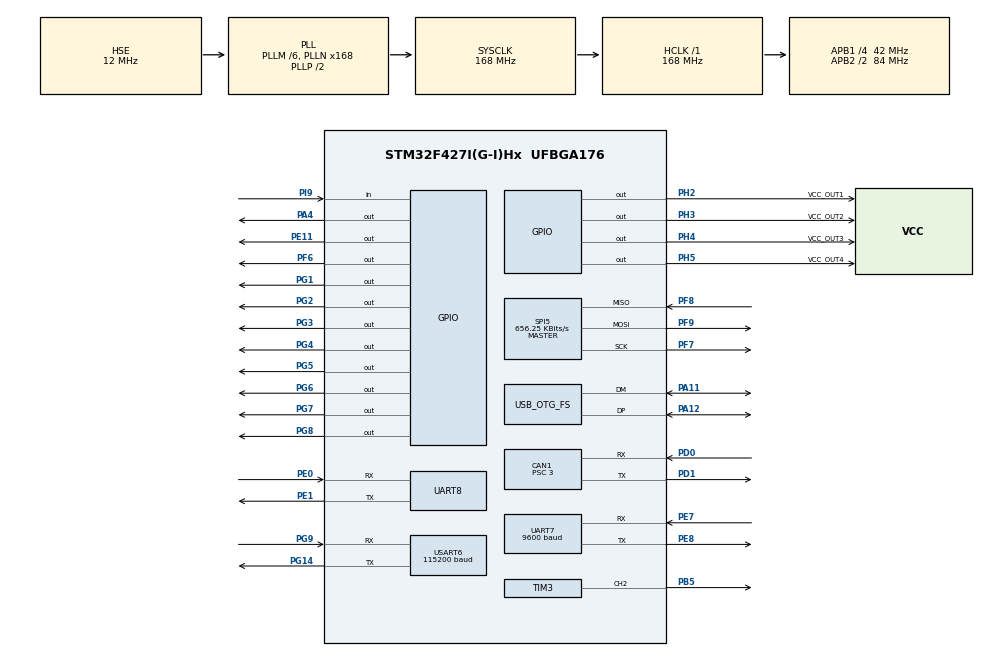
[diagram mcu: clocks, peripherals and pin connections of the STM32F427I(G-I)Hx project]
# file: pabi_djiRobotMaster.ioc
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CAN1.ABOM=ENABLE
CAN1.BS1=CAN_BS1_9TQ
CAN1.BS2=CAN_BS2_4TQ
CAN1.CalculateTimeQuantum=71.42857142857143
CAN1.Prescaler=3
FREERTOS.INCLUDE_xTaskGetHandle=1
FREERTOS.Tasks01=ledTask,0,128,LedTask,Default,NULL,Dynamic,NULL,NULL;defaultTask,0,128,StartDefaultTask,Default,NULL,Dynamic,NULL,NULL
FREERTOS.configENABLE_FPU=1
FREERTOS.configTOTAL_HEAP_SIZE=61440
Mcu.Family=STM32F4
Mcu.Name=STM32F427I(G-I)Hx
Mcu.Package=UFBGA176
NVIC.CAN1_RX0_IRQn=true\:5\:0\:false\:false\:true\:true\:true\:true
NVIC.OTG_FS_IRQn=true\:9\:0\:true\:false\:true\:false\:false\:true
NVIC.PriorityGroup=NVIC_PRIORITYGROUP_4
NVIC.TIM7_IRQn=true\:0\:0\:false\:false\:true\:false\:false\:true
NVIC.TimeBase=TIM7_IRQn
NVIC.TimeBaseIP=TIM7
NVIC.UART7_IRQn=true\:5\:0\:false\:false\:true\:true\:true\:true
NVIC.UART8_IRQn=true\:5\:0\:false\:false\:true\:true\:true\:true
NVIC.USART6_IRQn=true\:10\:0\:true\:false\:true\:false\:true\:true
PA11.Mode=Device_Only
PA11.Signal=USB_OTG_FS_DM
PA12.Mode=Device_Only
PA12.Signal=USB_OTG_FS_DP
PA13.Mode=Serial_Wire
PA13.Signal=SYS_JTMS-SWDIO
PA14.Mode=Serial_Wire
PA14.Signal=SYS_JTCK-SWCLK
PA4.GPIO_ModeDefaultOutputPP=GPIO_MODE_OUTPUT_PP
PA4.GPIO_PuPd=GPIO_PULLDOWN
PA4.Signal=GPIO_Output
PB5.GPIO_PuPd=GPIO_PULLUP
PB5.GPIO_Speed=GPIO_SPEED_FREQ_HIGH
PB5.Signal=S_TIM3_CH2
PD0.Mode=Master
PD0.Signal=CAN1_RX
PD1.Mode=Master
PD1.Signal=CAN1_TX
PE0.Mode=Asynchronous
PE0.Signal=UART8_RX
PE1.Mode=Asynchronous
PE1.Signal=UART8_TX
PE11.GPIO_ModeDefaultOutputPP=GPIO_MODE_OUTPUT_PP
PE11.GPIO_PuPd=GPIO_PULLDOWN
PE11.Signal=GPIO_Output
PE7.GPIO_PuPd=GPIO_PULLUP
PE7.Mode=Asynchronous
PE7.Signal=UART7_RX
PE8.Mode=Asynchronous
PE8.Signal=UART7_TX
PF6.GPIO_PuPd=GPIO_PULLUP
PF6.Signal=GPIO_Output
PF7.Mode=Full_Duplex_Master
PF7.Signal=SPI5_SCK
PF8.Mode=Full_Duplex_Master
PF8.Signal=SPI5_MISO
PF9.Mode=Full_Duplex_Master
PF9.Signal=SPI5_MOSI
PG1.PinState=GPIO_PIN_SET
PG1.Signal=GPIO_Output
PG14.Mode=Asynchronous
PG14.Signal=USART6_TX
PG2.PinState=GPIO_PIN_SET
PG2.Signal=GPIO_Output
PG3.PinState=GPIO_PIN_SET
PG3.Signal=GPIO_Output
PG4.PinState=GPIO_PIN_SET
PG4.Signal=GPIO_Output
PG5.PinState=GPIO_PIN_SET
PG5.Signal=GPIO_Output
PG6.PinState=GPIO_PIN_SET
PG6.Signal=GPIO_Output
PG7.PinState=GPIO_PIN_SET
PG7.Signal=GPIO_Output
PG8.PinState=GPIO_PIN_SET
PG8.Signal=GPIO_Output
PG9.Mode=Asynchronous
PG9.Signal=USART6_RX
PH0/OSC_IN.Mode=HSE-External-Oscillator
PH0/OSC_IN.Signal=RCC_OSC_IN
PH1/OSC_OUT.Mode=HSE-External-Oscillator
PH1/OSC_OUT.Signal=RCC_OSC_OUT
PH2.GPIO_Label=VCC_OUT1
PH2.GPIO_PuPd=GPIO_PULLDOWN
PH2.PinState=GPIO_PIN_SET
PH2.Signal=GPIO_Output
PH3.GPIO_Label=VCC_OUT2
PH3.GPIO_PuPd=GPIO_PULLDOWN
PH3.PinState=GPIO_PIN_SET
PH3.Signal=GPIO_Output
PH4.GPIO_Label=VCC_OUT3
PH4.GPIO_PuPd=GPIO_PULLDOWN
PH4.PinState=GPIO_PIN_SET
PH4.Signal=GPIO_Output
PH5.GPIO_Label=VCC_OUT4
PH5.GPIO_PuPd=GPIO_PULLDOWN
PH5.PinState=GPIO_PIN_SET
PH5.Signal=GPIO_Output
PI9.GPIO_PuPd=GPIO_PULLDOWN
PI9.Signal=GPIO_Input
ProjectManager.HeapSize=0x1000
ProjectManager.StackSize=0x2000
ProjectManager.TargetToolchain=MDK-ARM V5
RCC.48MHZClocksFreq_Value=48000000
RCC.AHBFreq_Value=168000000
RCC.APB1CLKDivider=RCC_HCLK_DIV4
RCC.APB1Freq_Value=42000000
RCC.APB1TimFreq_Value=84000000
RCC.APB2CLKDivider=RCC_HCLK_DIV2
RCC.APB2Freq_Value=84000000
RCC.APB2TimFreq_Value=168000000
RCC.CortexFreq_Value=168000000
RCC.HCLKFreq_Value=168000000
RCC.HSE_VALUE=12000000
RCC.HSI_VALUE=16000000
RCC.LSE_VALUE=32768
RCC.PLLM=6
RCC.PLLN=168
RCC.PLLQ=7
RCC.SYSCLKFreq_VALUE=168000000
RCC.SYSCLKSource=RCC_SYSCLKSOURCE_PLLCLK
RCC.VCOOutputFreq_Value=336000000
SH.S_TIM3_CH2.0=TIM3_CH2,PWM Generation2 CH2
SPI5.BaudRatePrescaler=SPI_BAUDRATEPRESCALER_128
SPI5.CalculateBaudRate=656.25 KBits/s
SPI5.Direction=SPI_DIRECTION_2LINES
SPI5.Mode=SPI_MODE_MASTER
SPI5.VirtualType=VM_MASTER
TIM3.Channel-PWM\ Generation2\ CH2=TIM_CHANNEL_2
TIM3.Period=4999
TIM3.Prescaler=1
UART7.BaudRate=9600
UART7.VirtualMode=Asynchronous
UART8.VirtualMode=Asynchronous
USART6.BaudRate=115200
USART6.VirtualMode=VM_ASYNC
USB_DEVICE.CLASS_NAME_FS=CDC
USB_DEVICE.VirtualMode-CDC_FS=Cdc
USB_DEVICE.VirtualModeFS=Cdc_FS
USB_OTG_FS.VirtualMode=Device_Only
VP_FREERTOS_VS_CMSIS_V1.Mode=CMSIS_V1
VP_SYS_VS_tim7.Mode=TIM7
VP_USB_DEVICE_VS_USB_DEVICE_CDC_FS.Mode=CDC_FS
board=custom

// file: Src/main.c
/* USER CODE BEGIN Header */
/**
  ******************************************************************************
  * @file           : main.c
  * @brief          : Main program body
  ******************************************************************************
  * @attention
  *
  * <h2><center>&copy; Copyright (c) 2020 STMicroelectronics.
  * All rights reserved.</center></h2>
  *
  * This software component is licensed by ST under Ultimate Liberty license
  * SLA0044, the "License"; You may not use this file except in compliance with
  * the License. You may obtain a copy of the License at:
  *                             www.st.com/SLA0044
  *
  ******************************************************************************
  */
/* USER CODE END Header */
#include "main.h"
#include "cmsis_os.h"
#include "usb_device.h"

/* USER CODE BEGIN Includes */
#include "user_task.h"
//#include "bsp_imu.h"
//#include "usart.h"
/* USER CODE END Includes */

CAN_HandleTypeDef hcan1;

SPI_HandleTypeDef hspi5;

TIM_HandleTypeDef htim3;

UART_HandleTypeDef huart7;
UART_HandleTypeDef huart8;
UART_HandleTypeDef huart6;

osThreadId ledTaskHandle;
osThreadId defaultTaskHandle;

void SystemClock_Config(void);
static void MX_GPIO_Init(void);
static void MX_USART6_UART_Init(void);
static void MX_SPI5_Init(void);
static void MX_TIM3_Init(void);
static void MX_CAN1_Init(void);
static void MX_UART7_Init(void);
static void MX_UART8_Init(void);
void LedTask(void const * argument);
void StartDefaultTask(void const * argument);

int main(void)
{

  /* MCU Configuration--------------------------------------------------------*/

  /* Reset of all peripherals, Initializes the Flash interface and the Systick. */
  HAL_Init();

  /* Configure the system clock */
  SystemClock_Config();

  /* Initialize all configured peripherals */
  MX_GPIO_Init();
  MX_USART6_UART_Init();
  MX_SPI5_Init();
  MX_TIM3_Init();
  MX_CAN1_Init();
  MX_UART7_Init();
  MX_UART8_Init();
  /* USER CODE BEGIN 2 */
//	usart6_tx_dma_init();
//	can_filter_init();
//	initRingbuffer();
//	MX_USB_DEVICE_Init();
//		//初始化mpu
//

  /* USER CODE END 2 */

  /* Create the thread(s) */
  /* definition and creation of ledTask */
  osThreadDef(ledTask, LedTask, osPriorityNormal, 0, 128);
  ledTaskHandle = osThreadCreate(osThread(ledTask), NULL);

  /* definition and creation of defaultTask */
  osThreadDef(defaultTask, StartDefaultTask, osPriorityNormal, 0, 128);
  defaultTaskHandle = osThreadCreate(osThread(defaultTask), NULL);

  /* Start scheduler */
  osKernelStart();

  /* We should never get here as control is now taken by the scheduler */
  /* Infinite loop */
  while (1)
  {

  }
}

void SystemClock_Config(void)
{
  RCC_OscInitTypeDef RCC_OscInitStruct = {0};
  RCC_ClkInitTypeDef RCC_ClkInitStruct = {0};

  /** Configure the main internal regulator output voltage
  */
  __HAL_RCC_PWR_CLK_ENABLE();
  __HAL_PWR_VOLTAGESCALING_CONFIG(PWR_REGULATOR_VOLTAGE_SCALE1);
  /** Initializes the RCC Oscillators according to the specified parameters
  * in the RCC_OscInitTypeDef structure.
  */
  RCC_OscInitStruct.OscillatorType = RCC_OSCILLATORTYPE_HSE;
  RCC_OscInitStruct.HSEState = RCC_HSE_ON;
  RCC_OscInitStruct.PLL.PLLState = RCC_PLL_ON;
  RCC_OscInitStruct.PLL.PLLSource = RCC_PLLSOURCE_HSE;
  RCC_OscInitStruct.PLL.PLLM = 6;
  RCC_OscInitStruct.PLL.PLLN = 168;
  RCC_OscInitStruct.PLL.PLLP = RCC_PLLP_DIV2;
  RCC_OscInitStruct.PLL.PLLQ = 7;
  if (HAL_RCC_OscConfig(&RCC_OscInitStruct) != HAL_OK)
  {
    Error_Handler();
  }
  /** Initializes the CPU, AHB and APB buses clocks
  */
  RCC_ClkInitStruct.ClockType = RCC_CLOCKTYPE_HCLK|RCC_CLOCKTYPE_SYSCLK
                              |RCC_CLOCKTYPE_PCLK1|RCC_CLOCKTYPE_PCLK2;
  RCC_ClkInitStruct.SYSCLKSource = RCC_SYSCLKSOURCE_PLLCLK;
  RCC_ClkInitStruct.AHBCLKDivider = RCC_SYSCLK_DIV1;
  RCC_ClkInitStruct.APB1CLKDivider = RCC_HCLK_DIV4;
  RCC_ClkInitStruct.APB2CLKDivider = RCC_HCLK_DIV2;

  if (HAL_RCC_ClockConfig(&RCC_ClkInitStruct, FLASH_LATENCY_5) != HAL_OK)
  {
    Error_Handler();
  }
}

static void MX_CAN1_Init(void)
{

  hcan1.Instance = CAN1;
  hcan1.Init.Prescaler = 3;
  hcan1.Init.Mode = CAN_MODE_NORMAL;
  hcan1.Init.SyncJumpWidth = CAN_SJW_1TQ;
  hcan1.Init.TimeSeg1 = CAN_BS1_9TQ;
  hcan1.Init.TimeSeg2 = CAN_BS2_4TQ;
  hcan1.Init.TimeTriggeredMode = DISABLE;
  hcan1.Init.AutoBusOff = ENABLE;
  hcan1.Init.AutoWakeUp = DISABLE;
  hcan1.Init.AutoRetransmission = DISABLE;
  hcan1.Init.ReceiveFifoLocked = DISABLE;
  hcan1.Init.TransmitFifoPriority = DISABLE;
  if (HAL_CAN_Init(&hcan1) != HAL_OK)
  {
    Error_Handler();
  }

}

static void MX_SPI5_Init(void)
{

  /* SPI5 parameter configuration*/
  hspi5.Instance = SPI5;
  hspi5.Init.Mode = SPI_MODE_MASTER;
  hspi5.Init.Direction = SPI_DIRECTION_2LINES;
  hspi5.Init.DataSize = SPI_DATASIZE_8BIT;
  hspi5.Init.CLKPolarity = SPI_POLARITY_LOW;
  hspi5.Init.CLKPhase = SPI_PHASE_1EDGE;
  hspi5.Init.NSS = SPI_NSS_SOFT;
  hspi5.Init.BaudRatePrescaler = SPI_BAUDRATEPRESCALER_128;
  hspi5.Init.FirstBit = SPI_FIRSTBIT_MSB;
  hspi5.Init.TIMode = SPI_TIMODE_DISABLE;
  hspi5.Init.CRCCalculation = SPI_CRCCALCULATION_DISABLE;
  hspi5.Init.CRCPolynomial = 10;
  if (HAL_SPI_Init(&hspi5) != HAL_OK)
  {
    Error_Handler();
  }

}

static void MX_TIM3_Init(void)
{

  TIM_MasterConfigTypeDef sMasterConfig = {0};
  TIM_OC_InitTypeDef sConfigOC = {0};

  htim3.Instance = TIM3;
  htim3.Init.Prescaler = 1;
  htim3.Init.CounterMode = TIM_COUNTERMODE_UP;
  htim3.Init.Period = 4999;
  htim3.Init.ClockDivision = TIM_CLOCKDIVISION_DIV1;
  htim3.Init.AutoReloadPreload = TIM_AUTORELOAD_PRELOAD_DISABLE;
  if (HAL_TIM_PWM_Init(&htim3) != HAL_OK)
  {
    Error_Handler();
  }
  sMasterConfig.MasterOutputTrigger = TIM_TRGO_RESET;
  sMasterConfig.MasterSlaveMode = TIM_MASTERSLAVEMODE_DISABLE;
  if (HAL_TIMEx_MasterConfigSynchronization(&htim3, &sMasterConfig) != HAL_OK)
  {
    Error_Handler();
  }
  sConfigOC.OCMode = TIM_OCMODE_PWM1;
  sConfigOC.Pulse = 0;
  sConfigOC.OCPolarity = TIM_OCPOLARITY_HIGH;
  sConfigOC.OCFastMode = TIM_OCFAST_DISABLE;
  if (HAL_TIM_PWM_ConfigChannel(&htim3, &sConfigOC, TIM_CHANNEL_2) != HAL_OK)
  {
    Error_Handler();
  }
  HAL_TIM_MspPostInit(&htim3);

}

static void MX_UART7_Init(void)
{

  huart7.Instance = UART7;
  huart7.Init.BaudRate = 115200;
  huart7.Init.WordLength = UART_WORDLENGTH_8B;
  huart7.Init.StopBits = UART_STOPBITS_1;
  huart7.Init.Parity = UART_PARITY_NONE;
  huart7.Init.Mode = UART_MODE_TX_RX;
  huart7.Init.HwFlowCtl = UART_HWCONTROL_NONE;
  huart7.Init.OverSampling = UART_OVERSAMPLING_16;
  if (HAL_UART_Init(&huart7) != HAL_OK)
  {
    Error_Handler();
  }

}

static void MX_UART8_Init(void)
{

  huart8.Instance = UART8;
  huart8.Init.BaudRate = 9600;
  huart8.Init.WordLength = UART_WORDLENGTH_8B;
  huart8.Init.StopBits = UART_STOPBITS_1;
  huart8.Init.Parity = UART_PARITY_NONE;
  huart8.Init.Mode = UART_MODE_TX_RX;
  huart8.Init.HwFlowCtl = UART_HWCONTROL_NONE;
  huart8.Init.OverSampling = UART_OVERSAMPLING_16;
  if (HAL_UART_Init(&huart8) != HAL_OK)
  {
    Error_Handler();
  }

}

static void MX_USART6_UART_Init(void)
{

  huart6.Instance = USART6;
  huart6.Init.BaudRate = 115200;
  huart6.Init.WordLength = UART_WORDLENGTH_8B;
  huart6.Init.StopBits = UART_STOPBITS_1;
  huart6.Init.Parity = UART_PARITY_NONE;
  huart6.Init.Mode = UART_MODE_TX_RX;
  huart6.Init.HwFlowCtl = UART_HWCONTROL_NONE;
  huart6.Init.OverSampling = UART_OVERSAMPLING_16;
  if (HAL_UART_Init(&huart6) != HAL_OK)
  {
    Error_Handler();
  }

}

static void MX_GPIO_Init(void)
{
  GPIO_InitTypeDef GPIO_InitStruct = {0};

  /* GPIO Ports Clock Enable */
  __HAL_RCC_GPIOE_CLK_ENABLE();
  __HAL_RCC_GPIOB_CLK_ENABLE();
  __HAL_RCC_GPIOG_CLK_ENABLE();
  __HAL_RCC_GPIOA_CLK_ENABLE();
  __HAL_RCC_GPIOD_CLK_ENABLE();
  __HAL_RCC_GPIOI_CLK_ENABLE();
  __HAL_RCC_GPIOH_CLK_ENABLE();
  __HAL_RCC_GPIOF_CLK_ENABLE();

  /*Configure GPIO pin Output Level */
  HAL_GPIO_WritePin(GPIOH, VCC_OUT1_Pin|VCC_OUT2_Pin|VCC_OUT3_Pin|VCC_OUT4_Pin, GPIO_PIN_SET);

  /*Configure GPIO pin Output Level */
  HAL_GPIO_WritePin(GPIOG, GPIO_PIN_8|GPIO_PIN_7|GPIO_PIN_6|GPIO_PIN_5
                          |GPIO_PIN_4|GPIO_PIN_3|GPIO_PIN_2|GPIO_PIN_1, GPIO_PIN_SET);

  /*Configure GPIO pin Output Level */
  HAL_GPIO_WritePin(GPIOF, GPIO_PIN_6, GPIO_PIN_RESET);

  /*Configure GPIO pin Output Level */
  HAL_GPIO_WritePin(GPIOA, GPIO_PIN_4, GPIO_PIN_RESET);

  /*Configure GPIO pin Output Level */
  HAL_GPIO_WritePin(GPIOE, GPIO_PIN_11, GPIO_PIN_RESET);

  /*Configure GPIO pin : PI9 */
  GPIO_InitStruct.Pin = GPIO_PIN_9;
  GPIO_InitStruct.Mode = GPIO_MODE_INPUT;
  GPIO_InitStruct.Pull = GPIO_PULLDOWN;
  HAL_GPIO_Init(GPIOI, &GPIO_InitStruct);

  /*Configure GPIO pins : VCC_OUT1_Pin VCC_OUT2_Pin VCC_OUT3_Pin VCC_OUT4_Pin */
  GPIO_InitStruct.Pin = VCC_OUT1_Pin|VCC_OUT2_Pin|VCC_OUT3_Pin|VCC_OUT4_Pin;
  GPIO_InitStruct.Mode = GPIO_MODE_OUTPUT_PP;
  GPIO_InitStruct.Pull = GPIO_PULLDOWN;
  GPIO_InitStruct.Speed = GPIO_SPEED_FREQ_LOW;
  HAL_GPIO_Init(GPIOH, &GPIO_InitStruct);

  /*Configure GPIO pins : PG8 PG7 PG6 PG5
                           PG4 PG3 PG2 PG1 */
  GPIO_InitStruct.Pin = GPIO_PIN_8|GPIO_PIN_7|GPIO_PIN_6|GPIO_PIN_5
                          |GPIO_PIN_4|GPIO_PIN_3|GPIO_PIN_2|GPIO_PIN_1;
  GPIO_InitStruct.Mode = GPIO_MODE_OUTPUT_PP;
  GPIO_InitStruct.Pull = GPIO_NOPULL;
  GPIO_InitStruct.Speed = GPIO_SPEED_FREQ_LOW;
  HAL_GPIO_Init(GPIOG, &GPIO_InitStruct);

  /*Configure GPIO pin : PF6 */
  GPIO_InitStruct.Pin = GPIO_PIN_6;
  GPIO_InitStruct.Mode = GPIO_MODE_OUTPUT_PP;
  GPIO_InitStruct.Pull = GPIO_PULLUP;
  GPIO_InitStruct.Speed = GPIO_SPEED_FREQ_LOW;
  HAL_GPIO_Init(GPIOF, &GPIO_InitStruct);

  /*Configure GPIO pin : PA4 */
  GPIO_InitStruct.Pin = GPIO_PIN_4;
  GPIO_InitStruct.Mode = GPIO_MODE_OUTPUT_PP;
  GPIO_InitStruct.Pull = GPIO_PULLDOWN;
  GPIO_InitStruct.Speed = GPIO_SPEED_FREQ_LOW;
  HAL_GPIO_Init(GPIOA, &GPIO_InitStruct);

  /*Configure GPIO pin : PE11 */
  GPIO_InitStruct.Pin = GPIO_PIN_11;
  GPIO_InitStruct.Mode = GPIO_MODE_OUTPUT_PP;
  GPIO_InitStruct.Pull = GPIO_PULLDOWN;
  GPIO_InitStruct.Speed = GPIO_SPEED_FREQ_LOW;
  HAL_GPIO_Init(GPIOE, &GPIO_InitStruct);

}

void LedTask(void const * argument)
{
  /* init code for USB_DEVICE */
  MX_USB_DEVICE_Init();
  for(;;)
  {
    osDelay(1);
  }
}

void StartDefaultTask(void const * argument)
{
  /* USER CODE BEGIN StartDefaultTask */
	MX_USB_DEVICE_Init();
  /* Infinite loop */
	user_taskInit();
  for(;;)
  {

    osDelay(1);
  }
  /* USER CODE END StartDefaultTask */
}

void HAL_TIM_PeriodElapsedCallback(TIM_HandleTypeDef *htim)
{
  if (htim->Instance == TIM7) {
    HAL_IncTick();
  }
}

void Error_Handler(void)
{
}

/************************ (C) COPYRIGHT STMicroelectronics *****END OF FILE****/

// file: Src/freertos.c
/* USER CODE BEGIN Header */
/**
 ******************************************************************************
 * File Name          : freertos.c
 * Description        : Code for freertos applications
 ******************************************************************************
 * @attention
 *
 * <h2><center>&copy; Copyright (c) 2020 STMicroelectronics.
 * All rights reserved.</center></h2>
 *
 * This software component is licensed by ST under Ultimate Liberty license
 * SLA0044, the "License"; You may not use this file except in compliance with
 * the License. You may obtain a copy of the License at:
 *                             www.st.com/SLA0044
 *
 ******************************************************************************
 */
/* USER CODE END Header */

#include "FreeRTOS.h"
#include "task.h"
#include "main.h"

/* USER CODE BEGIN Includes */
//#include "bsp_imu.h"
//#include "can.h"
//#include "gpio.h"
//#include "pid.h"
//#include "ringbuf.h"
//#include "tim.h"
//#include "usart.h"
//#include <stdio.h>
//#include <stdlib.h>
//#include <string.h>
/* USER CODE END Includes */

/* USER CODE BEGIN PD */
//#define COUNTOF(__BUFFER__)   (sizeof(__BUFFER__) / sizeof(*(__BUFFER__)))
#define TEMPERATURE_PID_KP 2000.0f // kp of temperature control PID
#define TEMPERATURE_PID_KI 0.6f    // ki of temperature control PID
#define TEMPERATURE_PID_KD 0.0f    // kd of temperature control PID

#define TEMPERATURE_PID_MAX_OUT 4500.0f  // max out of temperature control PID
#define TEMPERATURE_PID_MAX_IOUT 4400.0f // max iout of temperature control PID
/* USER CODE END PD */

/* GetIdleTaskMemory prototype (linked to static allocation support) */
void vApplicationGetIdleTaskMemory( StaticTask_t **ppxIdleTaskTCBBuffer, StackType_t **ppxIdleTaskStackBuffer, uint32_t *pulIdleTaskStackSize );

/* USER CODE BEGIN GET_IDLE_TASK_MEMORY */
static StaticTask_t xIdleTaskTCBBuffer;
static StackType_t xIdleStack[configMINIMAL_STACK_SIZE];

void vApplicationGetIdleTaskMemory( StaticTask_t **ppxIdleTaskTCBBuffer, StackType_t **ppxIdleTaskStackBuffer, uint32_t *pulIdleTaskStackSize )
{
  *ppxIdleTaskTCBBuffer = &xIdleTaskTCBBuffer;
  *ppxIdleTaskStackBuffer = &xIdleStack[0];
  *pulIdleTaskStackSize = configMINIMAL_STACK_SIZE;
  /* place for user code */
}
/* USER CODE END GET_IDLE_TASK_MEMORY */

/************************ (C) COPYRIGHT STMicroelectronics *****END OF FILE****/
